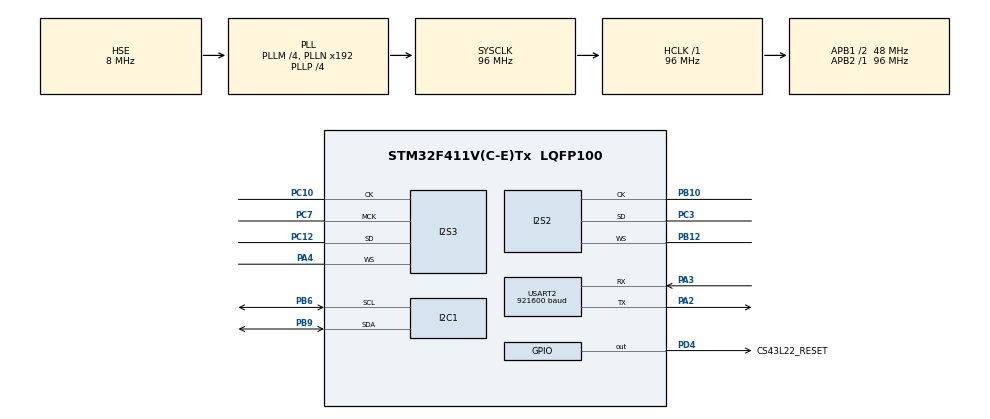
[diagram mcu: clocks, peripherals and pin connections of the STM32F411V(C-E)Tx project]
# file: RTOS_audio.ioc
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Dma.Request0=SPI2_RX
Dma.Request1=SPI3_TX
Dma.Request2=USART2_TX
Dma.SPI2_RX.0.Direction=DMA_PERIPH_TO_MEMORY
Dma.SPI2_RX.0.FIFOMode=DMA_FIFOMODE_DISABLE
Dma.SPI2_RX.0.Instance=DMA1_Stream3
Dma.SPI2_RX.0.MemDataAlignment=DMA_MDATAALIGN_HALFWORD
Dma.SPI2_RX.0.MemInc=DMA_MINC_ENABLE
Dma.SPI2_RX.0.Mode=DMA_CIRCULAR
Dma.SPI2_RX.0.PeriphDataAlignment=DMA_PDATAALIGN_HALFWORD
Dma.SPI2_RX.0.PeriphInc=DMA_PINC_DISABLE
Dma.SPI2_RX.0.Priority=DMA_PRIORITY_LOW
Dma.SPI3_TX.1.Direction=DMA_MEMORY_TO_PERIPH
Dma.SPI3_TX.1.FIFOMode=DMA_FIFOMODE_DISABLE
Dma.SPI3_TX.1.Instance=DMA1_Stream5
Dma.SPI3_TX.1.MemDataAlignment=DMA_MDATAALIGN_HALFWORD
Dma.SPI3_TX.1.MemInc=DMA_MINC_ENABLE
Dma.SPI3_TX.1.Mode=DMA_CIRCULAR
Dma.SPI3_TX.1.PeriphDataAlignment=DMA_PDATAALIGN_HALFWORD
Dma.SPI3_TX.1.PeriphInc=DMA_PINC_DISABLE
Dma.SPI3_TX.1.Priority=DMA_PRIORITY_LOW
Dma.USART2_TX.2.Direction=DMA_MEMORY_TO_PERIPH
Dma.USART2_TX.2.FIFOMode=DMA_FIFOMODE_DISABLE
Dma.USART2_TX.2.Instance=DMA1_Stream6
Dma.USART2_TX.2.MemDataAlignment=DMA_MDATAALIGN_BYTE
Dma.USART2_TX.2.MemInc=DMA_MINC_ENABLE
Dma.USART2_TX.2.Mode=DMA_NORMAL
Dma.USART2_TX.2.PeriphDataAlignment=DMA_PDATAALIGN_BYTE
Dma.USART2_TX.2.PeriphInc=DMA_PINC_DISABLE
Dma.USART2_TX.2.Priority=DMA_PRIORITY_MEDIUM
FREERTOS.BinarySemaphores01=pdmDataReady,Dynamic,NULL,Depleted;TXuart,Dynamic,NULL,Available
FREERTOS.Events01=wdgEvents,Dynamic,NULL
FREERTOS.Queues01=pcmTxQueue,3,256,1,Dynamic,NULL,NULL;pcmFftQueue,4,256,1,Dynamic,NULL,NULL
FREERTOS.Tasks01=pcmData,48,1024,start_pcmData,Default,NULL,Dynamic,NULL,NULL;pcmFFT,8,1024,start_pcmFFT,Default,NULL,Dynamic,NULL,NULL;wdgTask,8,256,start_wdgTask,Default,NULL,Dynamic,NULL,NULL
FREERTOS.configUSE_NEWLIB_REENTRANT=1
I2S2.AudioFreq=I2S_AUDIOFREQ_32K
I2S2.AudioFreqCustom=32000
I2S2.DataFormat=I2S_DATAFORMAT_16B
I2S2.ErrorAudioFreq=0.0 %
I2S2.FullDuplexMode=I2S_FULLDUPLEXMODE_DISABLE
I2S2.Instance=SPI$Index
I2S2.Mode=I2S_MODE_MASTER_RX
I2S2.RealAudioFreq=32.001 KHz
I2S2.Standard=I2S_STANDARD_MSB
I2S2.VirtualMode=I2S_MODE_MASTER
I2S3.AudioFreq=I2S_AUDIOFREQ_16K
I2S3.ErrorAudioFreq=0.0 %
I2S3.FullDuplexMode=I2S_FULLDUPLEXMODE_DISABLE
I2S3.Instance=SPI$Index
I2S3.RealAudioFreq=16.0 KHz
I2S3.VirtualMode=I2S_MODE_MASTER
IWDG.Prescaler=IWDG_PRESCALER_8
Mcu.Family=STM32F4
Mcu.Name=STM32F411V(C-E)Tx
Mcu.Package=LQFP100
NVIC.DMA1_Stream3_IRQn=true\:5\:0\:false\:false\:true\:true\:false\:true\:true
NVIC.DMA1_Stream5_IRQn=true\:5\:0\:false\:false\:true\:true\:false\:true\:true
NVIC.DMA1_Stream6_IRQn=true\:5\:0\:false\:false\:true\:true\:false\:true\:true
NVIC.PriorityGroup=NVIC_PRIORITYGROUP_4
NVIC.SPI2_IRQn=true\:5\:0\:false\:false\:true\:true\:true\:true\:true
NVIC.SPI3_IRQn=true\:5\:0\:false\:false\:true\:true\:true\:true\:true
NVIC.TIM1_UP_TIM10_IRQn=true\:15\:0\:false\:false\:true\:false\:false\:true\:true
NVIC.TimeBase=TIM1_UP_TIM10_IRQn
NVIC.TimeBaseIP=TIM1
NVIC.USART2_IRQn=true\:5\:0\:false\:false\:true\:true\:true\:true\:true
PA13.Mode=Serial_Wire
PA13.Signal=SYS_JTMS-SWDIO
PA14.Mode=Serial_Wire
PA14.Signal=SYS_JTCK-SWCLK
PA2.Mode=Asynchronous
PA2.Signal=USART2_TX
PA3.Mode=Asynchronous
PA3.Signal=USART2_RX
PA4.GPIO_Speed=GPIO_SPEED_FREQ_HIGH
PA4.Mode=Half_Duplex_Master
PA4.Signal=I2S3_WS
PB10.Mode=Half_Duplex_Master
PB10.Signal=I2S2_CK
PB12.Mode=Half_Duplex_Master
PB12.Signal=I2S2_WS
PB6.Mode=I2C
PB6.Signal=I2C1_SCL
PB9.Mode=I2C
PB9.Signal=I2C1_SDA
PC10.GPIO_Speed=GPIO_SPEED_FREQ_HIGH
PC10.Mode=Half_Duplex_Master
PC10.Signal=I2S3_CK
PC12.GPIO_Speed=GPIO_SPEED_FREQ_HIGH
PC12.Mode=Half_Duplex_Master
PC12.Signal=I2S3_SD
PC3.Mode=Half_Duplex_Master
PC3.Signal=I2S2_SD
PC7.GPIO_Speed=GPIO_SPEED_FREQ_HIGH
PC7.Mode=Master_Clock_Activated
PC7.Signal=I2S3_MCK
PD4.GPIO_Label=CS43L22_RESET
PD4.Signal=GPIO_Output
PH0\ -\ OSC_IN.Mode=HSE-External-Oscillator
PH0\ -\ OSC_IN.Signal=RCC_OSC_IN
PH1\ -\ OSC_OUT.Mode=HSE-External-Oscillator
PH1\ -\ OSC_OUT.Signal=RCC_OSC_OUT
ProjectManager.HeapSize=0x200
ProjectManager.StackSize=0x400
ProjectManager.TargetToolchain=STM32CubeIDE
RCC.48MHZClocksFreq_Value=48000000
RCC.AHBFreq_Value=96000000
RCC.APB1CLKDivider=RCC_HCLK_DIV2
RCC.APB1Freq_Value=48000000
RCC.APB1TimFreq_Value=96000000
RCC.APB2Freq_Value=96000000
RCC.APB2TimFreq_Value=96000000
RCC.CortexFreq_Value=96000000
RCC.HCLKFreq_Value=96000000
RCC.HSE_VALUE=8000000
RCC.HSI_VALUE=16000000
RCC.LSE_VALUE=32768
RCC.PLLI2SM=8
RCC.PLLI2SN=213
RCC.PLLM=4
RCC.PLLP=RCC_PLLP_DIV4
RCC.PLLQ=8
RCC.PLLSourceVirtual=RCC_PLLSOURCE_HSE
RCC.SYSCLKFreq_VALUE=96000000
RCC.SYSCLKSource=RCC_SYSCLKSOURCE_PLLCLK
RCC.VCOOutputFreq_Value=384000000
USART2.BaudRate=921600
USART2.VirtualMode=VM_ASYNC
VP_CRC_VS_CRC.Mode=CRC_Activate
VP_FREERTOS_VS_CMSIS_V2.Mode=CMSIS_V2
VP_IWDG_VS_IWDG.Mode=IWDG_Activate
VP_SYS_VS_tim1.Mode=TIM1
board=STM32F411E-DISCO

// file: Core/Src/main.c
/* USER CODE BEGIN Header */
/**
  ******************************************************************************
  * @file           : main.c
  * @brief          : Main program body
  ******************************************************************************
  * @attention
  *
  * Copyright (c) 2026 STMicroelectronics.
  * All rights reserved.
  *
  * This software is licensed under terms that can be found in the LICENSE file
  * in the root directory of this software component.
  * If no LICENSE file comes with this software, it is provided AS-IS.
  *
  ******************************************************************************
  */
/* USER CODE END Header */
#include "main.h"
#include "cmsis_os.h"
#include "crc.h"
#include "dma.h"
#include "i2c.h"
#include "i2s.h"
#include "iwdg.h"
#include "usart.h"
#include "gpio.h"

/* USER CODE BEGIN Includes */
#include <string.h>
/* USER CODE END Includes */

void SystemClock_Config(void);
void PeriphCommonClock_Config(void);
void MX_FREERTOS_Init(void);

int main(void)
{

  /* MCU Configuration--------------------------------------------------------*/

  /* Reset of all peripherals, Initializes the Flash interface and the Systick. */
  HAL_Init();

  /* Configure the system clock */
  SystemClock_Config();

  /* Configure the peripherals common clocks */
  PeriphCommonClock_Config();

  /* Initialize all configured peripherals */
  MX_GPIO_Init();
  MX_DMA_Init();
  MX_CRC_Init();
  MX_I2S2_Init();
  MX_I2S3_Init();
  MX_I2C1_Init();
  MX_USART2_UART_Init();
  MX_IWDG_Init();
  /* USER CODE BEGIN 2 */

  char test_string[] = "Hello from UART\r\n";
  HAL_UART_Transmit(&huart2, (uint8_t *)test_string, strlen(test_string), HAL_MAX_DELAY);

  // avoid watchdog resets while debugging
  __HAL_DBGMCU_FREEZE_IWDG();

  // MCU restarted by watchdog
  if (__HAL_RCC_GET_FLAG(RCC_FLAG_IWDGRST))
  {
    char wdg_msg[] = "Reset by watchdog\r\n";
    HAL_UART_Transmit(&huart2, (uint8_t *)wdg_msg, strlen(wdg_msg), HAL_MAX_DELAY);
  }
  __HAL_RCC_CLEAR_RESET_FLAGS();

  /* USER CODE END 2 */

  /* Init scheduler */
  osKernelInitialize();  /* Call init function for freertos objects (in cmsis_os2.c) */
  MX_FREERTOS_Init();

  /* Start scheduler */
  osKernelStart();

  /* We should never get here as control is now taken by the scheduler */

  /* Infinite loop */
  while (1)
  {

  }
}

void SystemClock_Config(void)
{
  RCC_OscInitTypeDef RCC_OscInitStruct = {0};
  RCC_ClkInitTypeDef RCC_ClkInitStruct = {0};

  /** Configure the main internal regulator output voltage
  */
  __HAL_RCC_PWR_CLK_ENABLE();
  __HAL_PWR_VOLTAGESCALING_CONFIG(PWR_REGULATOR_VOLTAGE_SCALE1);

  /** Initializes the RCC Oscillators according to the specified parameters
  * in the RCC_OscInitTypeDef structure.
  */
  RCC_OscInitStruct.OscillatorType = RCC_OSCILLATORTYPE_LSI|RCC_OSCILLATORTYPE_HSE;
  RCC_OscInitStruct.HSEState = RCC_HSE_ON;
  RCC_OscInitStruct.LSIState = RCC_LSI_ON;
  RCC_OscInitStruct.PLL.PLLState = RCC_PLL_ON;
  RCC_OscInitStruct.PLL.PLLSource = RCC_PLLSOURCE_HSE;
  RCC_OscInitStruct.PLL.PLLM = 4;
  RCC_OscInitStruct.PLL.PLLN = 192;
  RCC_OscInitStruct.PLL.PLLP = RCC_PLLP_DIV4;
  RCC_OscInitStruct.PLL.PLLQ = 8;
  if (HAL_RCC_OscConfig(&RCC_OscInitStruct) != HAL_OK)
  {
    Error_Handler();
  }

  /** Initializes the CPU, AHB and APB buses clocks
  */
  RCC_ClkInitStruct.ClockType = RCC_CLOCKTYPE_HCLK|RCC_CLOCKTYPE_SYSCLK
                              |RCC_CLOCKTYPE_PCLK1|RCC_CLOCKTYPE_PCLK2;
  RCC_ClkInitStruct.SYSCLKSource = RCC_SYSCLKSOURCE_PLLCLK;
  RCC_ClkInitStruct.AHBCLKDivider = RCC_SYSCLK_DIV1;
  RCC_ClkInitStruct.APB1CLKDivider = RCC_HCLK_DIV2;
  RCC_ClkInitStruct.APB2CLKDivider = RCC_HCLK_DIV1;

  if (HAL_RCC_ClockConfig(&RCC_ClkInitStruct, FLASH_LATENCY_3) != HAL_OK)
  {
    Error_Handler();
  }
}

void PeriphCommonClock_Config(void)
{
  RCC_PeriphCLKInitTypeDef PeriphClkInitStruct = {0};

  /** Initializes the peripherals clock
  */
  PeriphClkInitStruct.PeriphClockSelection = RCC_PERIPHCLK_I2S;
  PeriphClkInitStruct.PLLI2S.PLLI2SN = 213;
  PeriphClkInitStruct.PLLI2S.PLLI2SM = 8;
  PeriphClkInitStruct.PLLI2S.PLLI2SR = 2;
  if (HAL_RCCEx_PeriphCLKConfig(&PeriphClkInitStruct) != HAL_OK)
  {
    Error_Handler();
  }
}

void HAL_TIM_PeriodElapsedCallback(TIM_HandleTypeDef *htim)
{
  if (htim->Instance == TIM1)
  {
    HAL_IncTick();
  }
}

void Error_Handler(void)
{
  __disable_irq();
  while (1)
  {
  }
}

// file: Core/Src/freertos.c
/* USER CODE BEGIN Header */
/**
  ******************************************************************************
  * File Name          : freertos.c
  * Description        : Code for freertos applications
  ******************************************************************************
  * @attention
  *
  * Copyright (c) 2026 STMicroelectronics.
  * All rights reserved.
  *
  * This software is licensed under terms that can be found in the LICENSE file
  * in the root directory of this software component.
  * If no LICENSE file comes with this software, it is provided AS-IS.
  *
  ******************************************************************************
  */
/* USER CODE END Header */

#include "FreeRTOS.h"
#include "task.h"
#include "main.h"
#include "cmsis_os.h"

/* USER CODE BEGIN Includes */
#include "AudioApp.h"

/* USER CODE END Includes */

/* Definitions for pcmData */
osThreadId_t pcmDataHandle;
const osThreadAttr_t pcmData_attributes = {
  .name = "pcmData",
  .stack_size = 1024 * 4,
  .priority = (osPriority_t) osPriorityRealtime,
};
/* Definitions for pcmFFT */
osThreadId_t pcmFFTHandle;
const osThreadAttr_t pcmFFT_attributes = {
  .name = "pcmFFT",
  .stack_size = 1024 * 4,
  .priority = (osPriority_t) osPriorityLow,
};
/* Definitions for wdgTask */
osThreadId_t wdgTaskHandle;
const osThreadAttr_t wdgTask_attributes = {
  .name = "wdgTask",
  .stack_size = 256 * 4,
  .priority = (osPriority_t) osPriorityLow,
};
/* Definitions for pcmTxQueue */
osMessageQueueId_t pcmTxQueueHandle;
const osMessageQueueAttr_t pcmTxQueue_attributes = {
  .name = "pcmTxQueue"
};
/* Definitions for pcmFftQueue */
osMessageQueueId_t pcmFftQueueHandle;
const osMessageQueueAttr_t pcmFftQueue_attributes = {
  .name = "pcmFftQueue"
};
/* Definitions for pdmDataReady */
osSemaphoreId_t pdmDataReadyHandle;
const osSemaphoreAttr_t pdmDataReady_attributes = {
  .name = "pdmDataReady"
};
/* Definitions for TXuart */
osSemaphoreId_t TXuartHandle;
const osSemaphoreAttr_t TXuart_attributes = {
  .name = "TXuart"
};
/* Definitions for wdgEvents */
osEventFlagsId_t wdgEventsHandle;
const osEventFlagsAttr_t wdgEvents_attributes = {
  .name = "wdgEvents"
};

void start_pcmData(void *argument);
void start_pcmFFT(void *argument);
void start_wdgTask(void *argument);

void MX_FREERTOS_Init(void); /* (MISRA C 2004 rule 8.1) */

void MX_FREERTOS_Init(void) {

  /* Create the semaphores(s) */
  /* creation of pdmDataReady */
  pdmDataReadyHandle = osSemaphoreNew(1, 0, &pdmDataReady_attributes);

  /* creation of TXuart */
  TXuartHandle = osSemaphoreNew(1, 1, &TXuart_attributes);

  /* Create the queue(s) */
  /* creation of pcmTxQueue */
  pcmTxQueueHandle = osMessageQueueNew (3, 256, &pcmTxQueue_attributes);

  /* creation of pcmFftQueue */
  pcmFftQueueHandle = osMessageQueueNew (4, 256, &pcmFftQueue_attributes);

  /* Create the thread(s) */
  /* creation of pcmData */
  pcmDataHandle = osThreadNew(start_pcmData, NULL, &pcmData_attributes);

  /* creation of pcmFFT */
  pcmFFTHandle = osThreadNew(start_pcmFFT, NULL, &pcmFFT_attributes);

  /* creation of wdgTask */
  wdgTaskHandle = osThreadNew(start_wdgTask, NULL, &wdgTask_attributes);

  /* Create the event(s) */
  /* creation of wdgEvents */
  wdgEventsHandle = osEventFlagsNew(&wdgEvents_attributes);

}

void start_pcmData(void *argument)
{
  /* USER CODE BEGIN start_pcmData */
	AudioTask_Run();
  /* USER CODE END start_pcmData */
}

void start_pcmFFT(void *argument)
{
  /* USER CODE BEGIN start_pcmFFT */
	FftTask_Run();
  /* USER CODE END start_pcmFFT */
}

void start_wdgTask(void *argument)
{
  /* USER CODE BEGIN start_wdgTask */
  WdgTask_Run();
  /* USER CODE END start_wdgTask */
}
